AUTOSAR XML (schema 4-2-2)
package /ComponentTypes
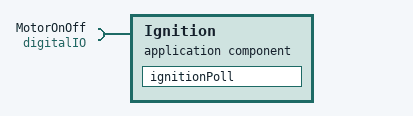
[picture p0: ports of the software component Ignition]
  application sw component type Ignition
    require port MotorOnOff: nonqueued-receiver-com-spec{data-element=boolean, init-value=0}, required-interface=digitalIO
    behavior Ignition_InternalBehavior
      init event ignitionPoll_InitEvent: start-on-event=ignitionPoll
      runnable ignitionPoll
        data-receive-point-by-arguments:
          access REC_MotorOnOff_boolean: accessed-variable=MotorOnOff.boolean
  swc implementation Ignition_Implementation: behavior=Ignition_InternalBehavior
